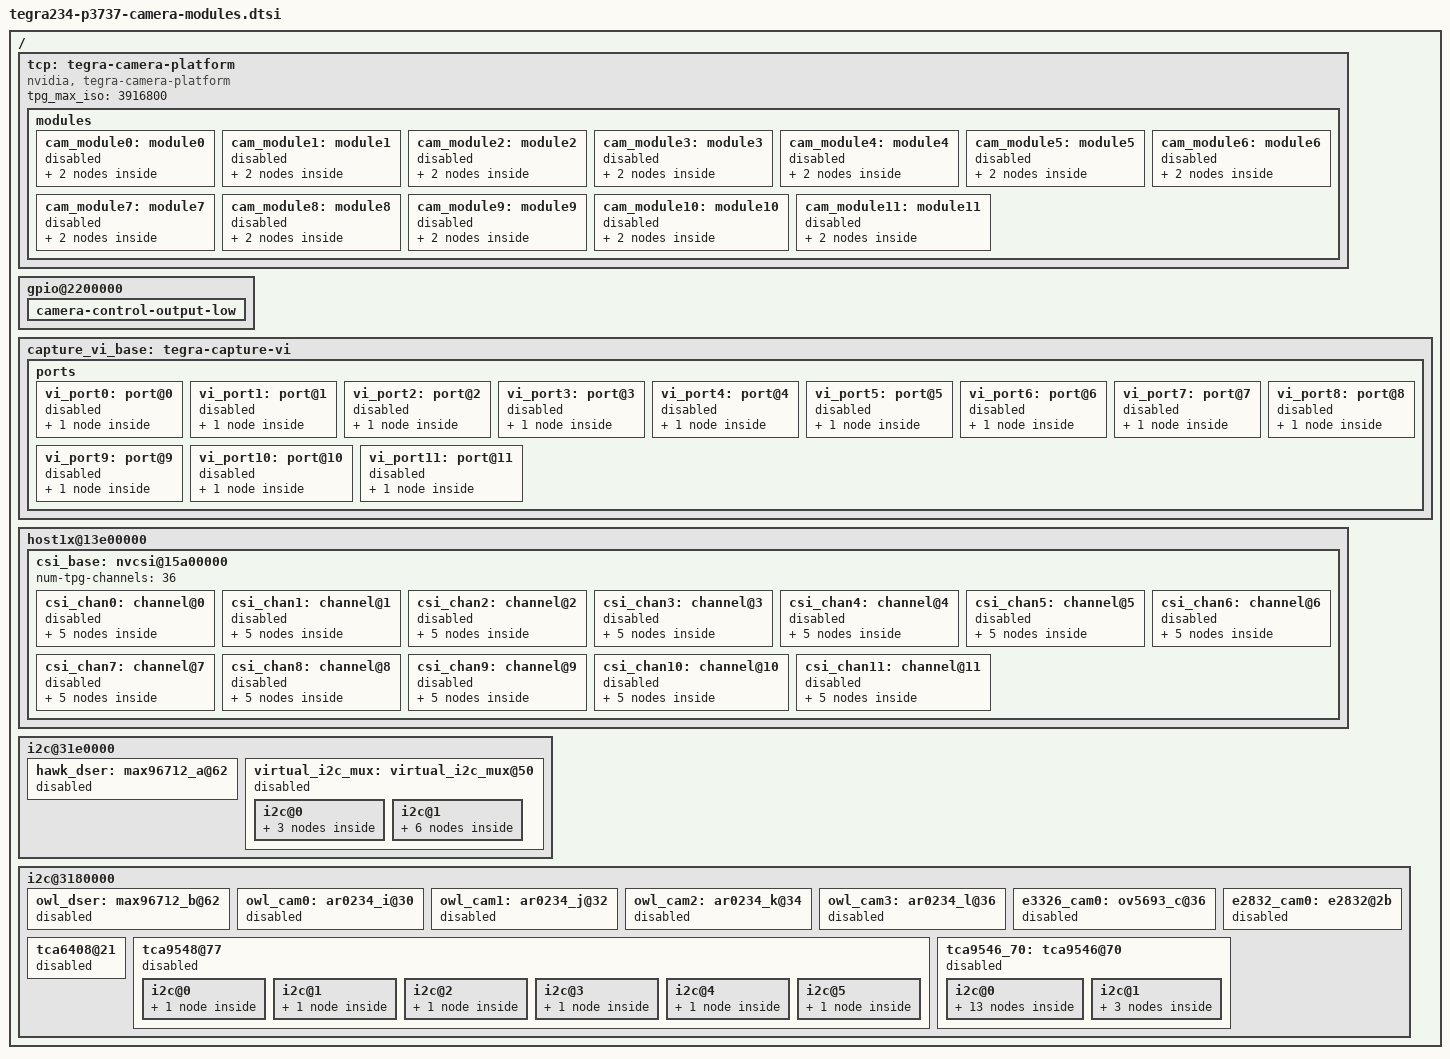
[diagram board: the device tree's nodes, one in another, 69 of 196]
/*
 * Copyright (c) 2023, NVIDIA CORPORATION.  All rights reserved.
 *
 * This program is free software; you can redistribute it and/or modify it
 * under the terms and conditions of the GNU General Public License,
 * version 2, as published by the Free Software Foundation.
 *
 * This program is distributed in the hope it will be useful, but WITHOUT
 * ANY WARRANTY; without even the implied warranty of MERCHANTABILITY or
 * FITNESS FOR A PARTICULAR PURPOSE.  See the GNU General Public License for
 * more details.
 *
 * You should have received a copy of the GNU General Public License
 * along with this program.  If not, see <http://www.gnu.org/licenses/>.
 */

/* These headers don't exist yet.
 * TODO: add below headers for corresponding sensor modules.
 * #include "tegra234-p3737-0000-camera-e3377-a00.dtsi"
 * #include "tegra234-p3737-0000-camera-e3326-a00.dtsi"
 * #include "tegra234-p3737-0000-camera-vivid.dtsi"
 * #include "tegra234-p3737-0000-camera-imx274-a00.dtsi"
 */

#include "tegra234-p3737-0000-camera-ar0234-a00.dtsi"
#include "tegra234-p3737-0000-camera-p3762-a00.dtsi"
#include "tegra234-p3737-0000-camera-e3331-a00.dtsi"
#include "tegra234-p3737-0000-camera-e3333-a00.dtsi"
#include "tegra234-p3737-0000-camera-imx185-a00.dtsi"
#include "tegra234-p3737-0000-camera-imx390-a00.dtsi"
#include "tegra234-p3737-0000-camera-imx274-dual.dtsi"


#define CAM0_RST_L	TEGRA234_MAIN_GPIO(H, 3)
#define CAM0_PWDN	TEGRA234_MAIN_GPIO(H, 6)
#define CAM1_RST_L	TEGRA234_MAIN_GPIO(AC, 1)
#define CAM1_PWDN	TEGRA234_MAIN_GPIO(AC, 0)

/ {
	tegra-camera-platform {
		/**
		* tpg_max_iso = <>;
		* Max iso bw for 6 streams of tpg
		* streams * nvcsi_freq * PG_bitrate / RG10 * BPP
		* 6 * 102Mhz * 32 bits/ 10 bits * 2 Bps
		* = 3916.8 MBps
		*/
		tpg_max_iso = <3916800>;
	};

	/* set camera gpio direction to output */
	gpio@2200000 {
		camera-control-output-low {
			gpio-hog;
			output-low;
			gpios = <CAM0_RST_L 0 CAM0_PWDN 0
				 CAM1_RST_L 0 CAM1_PWDN 0>;
			label = "cam0-rst", "cam0-pwdn",
				"cam1-rst", "cam1-pwdn";
		};
	};

	/* all cameras are disabled by default */
	capture_vi_base: tegra-capture-vi {
		ports {
			vi_port0: port@0 {
				status = "disabled";
				vi_in0: endpoint {
					vc-id = <0>;
					status = "disabled";
				};
			};
			vi_port1: port@1 {
				status = "disabled";
				vi_in1: endpoint {
					vc-id = <0>;
					status = "disabled";
				};
			};
			vi_port2: port@2 {
				status = "disabled";
				vi_in2: endpoint {
					vc-id = <0>;
					status = "disabled";
				};
			};
			vi_port3: port@3 {
				status = "disabled";
				vi_in3: endpoint {
					vc-id = <0>;
					status = "disabled";
				};
			};
			vi_port4: port@4 {
				status = "disabled";
				vi_in4: endpoint {
					vc-id = <0>;
					status = "disabled";
				};
			};
			vi_port5: port@5 {
				status = "disabled";
				vi_in5: endpoint {
					vc-id = <0>;
					status = "disabled";
				};
			};
			vi_port6: port@6 {
				status = "disabled";
				vi_in6: endpoint {
					vc-id = <0>;
					status = "disabled";
				};
			};
			vi_port7: port@7 {
				status = "disabled";
				vi_in7: endpoint {
					vc-id = <0>;
					status = "disabled";
				};
			};
			vi_port8: port@8 {
				status = "disabled";
				vi_in8: endpoint {
					vc-id = <0>;
					status = "disabled";
				};
			};
			vi_port9: port@9 {
				status = "disabled";
				vi_in9: endpoint {
					vc-id = <0>;
					status = "disabled";
				};
			};
			vi_port10: port@10 {
				status = "disabled";
				vi_in10: endpoint {
					vc-id = <0>;
					status = "disabled";
				};
			};
			vi_port11: port@11 {
				status = "disabled";
				vi_in11: endpoint {
					vc-id = <0>;
					status = "disabled";
				};
			};
		};
	};

	host1x@13e00000 {
		csi_base: nvcsi@15a00000 {
			num-tpg-channels = <36>;
			csi_chan0: channel@0 {
				status = "disabled";
				ports {
					csi_chan0_port0: port@0 {
						status = "disabled";
						csi_in0: endpoint@0 {
							status = "disabled";
						};
					};
					csi_chan0_port1: port@1 {
						status = "disabled";
						csi_out0: endpoint@1 {
							status = "disabled";
						};
					};
				};
			};
			csi_chan1: channel@1 {
				status = "disabled";
				ports {
					csi_chan1_port0: port@0 {
						status = "disabled";
						csi_in1: endpoint@2 {
							status = "disabled";
						};
					};
					csi_chan1_port1: port@1 {
						status = "disabled";
						csi_out1: endpoint@3 {
							status = "disabled";
						};
					};
				};
			};
			csi_chan2: channel@2 {
				status = "disabled";
				ports {
					csi_chan2_port0: port@0 {
						status = "disabled";
						csi_in2: endpoint@4 {
							status = "disabled";
						};
					};
					csi_chan2_port1: port@1 {
						status = "disabled";
						csi_out2: endpoint@5 {
							status = "disabled";
						};
					};
				};
			};
			csi_chan3: channel@3 {
				status = "disabled";
				ports {
					csi_chan3_port0: port@0 {
						status = "disabled";
						csi_in3: endpoint@6 {
							status = "disabled";
						};
					};
					csi_chan3_port1: port@1 {
						status = "disabled";
						csi_out3: endpoint@7 {
							status = "disabled";
						};
					};
				};
			};
			csi_chan4: channel@4 {
				status = "disabled";
				ports {
					csi_chan4_port0: port@0 {
						status = "disabled";
						csi_in4: endpoint@8 {
							status = "disabled";
						};
					};
					csi_chan4_port1: port@1 {
						status = "disabled";
						csi_out4: endpoint@9 {
							status = "disabled";
						};
					};
				};
			};
			csi_chan5: channel@5 {
				status = "disabled";
				ports {
					csi_chan5_port0: port@0 {
						status = "disabled";
						csi_in5: endpoint@10 {
							status = "disabled";
						};
					};
					csi_chan5_port1: port@1 {
						status = "disabled";
						csi_out5: endpoint@11 {
							status = "disabled";
						};
					};
				};
			};
			csi_chan6: channel@6 {
				status = "disabled";
				ports {
					csi_chan6_port0: port@0 {
						status = "disabled";
						csi_in6: endpoint@12 {
							status = "disabled";
						};
					};
					csi_chan6_port1: port@1 {
						status = "disabled";
						csi_out6: endpoint@13 {
							status = "disabled";
						};
					};
				};
			};
			csi_chan7: channel@7 {
				status = "disabled";
				ports {
					csi_chan7_port0: port@0 {
						status = "disabled";
						csi_in7: endpoint@14 {
							status = "disabled";
						};
					};
					csi_chan7_port1: port@1 {
						status = "disabled";
						csi_out7: endpoint@15 {
							status = "disabled";
						};
					};
				};
			};
			csi_chan8: channel@8 {
				status = "disabled";
				ports {
					csi_chan8_port0: port@0 {
						status = "disabled";
						csi_in8: endpoint@16 {
							status = "disabled";
						};
					};
					csi_chan8_port1: port@1 {
						status = "disabled";
						csi_out8: endpoint@17 {
							status = "disabled";
						};
					};
				};
			};
			csi_chan9: channel@9 {
				status = "disabled";
				ports {
					csi_chan9_port0: port@0 {
						status = "disabled";
						csi_in9: endpoint@18 {
							status = "disabled";
						};
					};
					csi_chan9_port1: port@1 {
						status = "disabled";
						csi_out9: endpoint@19 {
							status = "disabled";
						};
					};
				};
			};
			csi_chan10: channel@10 {
				status = "disabled";
				ports {
					csi_chan10_port0: port@0 {
						status = "disabled";
						csi_in10: endpoint@20 {
							status = "disabled";
						};
					};
					csi_chan10_port1: port@1 {
						status = "disabled";
						csi_out10: endpoint@21 {
							status = "disabled";
						};
					};
				};
			};
			csi_chan11: channel@11 {
				status = "disabled";
				ports {
					csi_chan11_port0: port@0 {
						status = "disabled";
						csi_in11: endpoint@22 {
							status = "disabled";
						};
					};
					csi_chan11_port1: port@1 {
						status = "disabled";
						csi_out11: endpoint@23 {
							status = "disabled";
						};
					};
				};
			};
		};
	};

	i2c@31e0000 {
		hawk_dser: max96712_a@62 {
			status = "disabled";
		};
		virtual_i2c_mux: virtual_i2c_mux@50 {
			status = "disabled";
			i2c@0 {
				hawk_bmi: bmi088_a@69 {
					status = "disabled";
				};
				hawk_cam0: ar0234_a@30 {
					status = "disabled";
				};
				hawk_cam1: ar0234_b@31 {
					status = "disabled";
				};
			};
			i2c@1 {
				hawk_cam2: ar0234_c@32 {
					status = "disabled";
				};
				hawk_cam3: ar0234_d@33 {
					status = "disabled";
				};
				hawk_cam4: ar0234_e@34 {
					status = "disabled";
				};
				hawk_cam5: ar0234_f@35 {
					status = "disabled";
				};
				hawk_cam6: ar0234_g@36 {
					status = "disabled";
				};
				hawk_cam7: ar0234_h@37 {
					status = "disabled";
				};
			};
		};
	};
	i2c@3180000 {
		owl_dser: max96712_b@62 {
			status = "disabled";
		};
		owl_cam0: ar0234_i@30 {
			status = "disabled";
		};
		owl_cam1: ar0234_j@32 {
			status = "disabled";
		};
		owl_cam2: ar0234_k@34 {
			status = "disabled";
		};
		owl_cam3: ar0234_l@36 {
			status = "disabled";
		};
		e3326_cam0: ov5693_c@36 {
			status = "disabled";
		};
		e2832_cam0: e2832@2b {
			status = "disabled";
		};
		tca6408@21 {
			status = "disabled";
		};
		tca9548@77 {
			status = "disabled";
			i2c@0 {
				e3333_cam0: ov5693_a@36 {
					status = "disabled";
				};
			};
			i2c@1 {
				e3333_cam1: ov5693_b@36 {
					status = "disabled";
				};
			};
			i2c@2 {
				e3333_cam2: ov5693_c@36 {
					status = "disabled";
				};
			};
			i2c@3 {
				e3333_cam3: ov5693_d@36 {
					status = "disabled";
				};
			};
			i2c@4 {
				e3333_cam4: ov5693_e@36 {
					status = "disabled";
				};
			};
			i2c@5 {
				e3333_cam5: ov5693_g@36 {
					status = "disabled";
				};
			};
		};
		tca9546_70: tca9546@70 {
			status = "disabled";
			i2c@0 {
				dual_hawk0:dual_hawk_a@18 {
					status = "disabled";
				};
				dual_hawk1:dual_hawk_b@10 {
					status = "disabled";
				};
				pca9570_a_24: pca9570_a@24 {
					status = "disabled";
				};
				imx274_cam0: imx274_a@1a {
					status = "disabled";
				};
				imx185_cam0: imx185_a@1a {
					status = "disabled";
				};
				e3331_cam0: imx318_a@10 {
					status = "disable";
				};
				max96712_dser: single_max96712_a@62 {
					status = "disabled";
				};
				max9296_dser: max9296@48 {
					status = "disabled";
				};
				max9295_prim: max9295_prim@62 {
					status = "disabled";
				};
				max9295_ser0: max9295_a@40 {
					status = "disabled";
				};
				max9295_ser1: max9295_b@60 {
					status = "disabled";
				};
				imx390_cam0: imx390_a@1b {
					status = "disabled";
				};
				imx390_cam1: imx390_b@1c {
					status = "disabled";
				};
			};
			i2c@1 {
				dual_hawk2:dual_hawk_c@18 {
					status = "disabled";
				};
				dual_hawk3:dual_hawk_d@10 {
					status = "disabled";
				};
				imx274_cam1: imx274_c@1a {
					status = "disabled";
				};
			};
		};
	};

	tcp: tegra-camera-platform {
		compatible = "nvidia, tegra-camera-platform";
		modules {
			cam_module0: module0 {
				status = "disabled";
				cam_module0_drivernode0: drivernode0 {
					status = "disabled";
				};
				cam_module0_drivernode1: drivernode1 {
					status = "disabled";
					pcl_id = "v4l2_lens";
				};
			};
			cam_module1: module1 {
				status = "disabled";
				cam_module1_drivernode0: drivernode0 {
					status = "disabled";
				};
				cam_module1_drivernode1: drivernode1 {
					status = "disabled";
					pcl_id = "v4l2_lens";
				};
			};
			cam_module2: module2 {
				status = "disabled";
				cam_module2_drivernode0: drivernode0 {
					status = "disabled";
				};
				cam_module2_drivernode1: drivernode1 {
					status = "disabled";
					pcl_id = "v4l2_lens";
				};
			};
			cam_module3: module3 {
				status = "disabled";
				cam_module3_drivernode0: drivernode0 {
					status = "disabled";
				};
				cam_module3_drivernode1: drivernode1 {
					status = "disabled";
					pcl_id = "v4l2_lens";
				};
			};
			cam_module4: module4 {
				status = "disabled";
				cam_module4_drivernode0: drivernode0 {
					status = "disabled";
				};
				cam_module4_drivernode1: drivernode1 {
					status = "disabled";
					pcl_id = "v4l2_lens";
				};
			};
			cam_module5: module5 {
				status = "disabled";
				cam_module5_drivernode0: drivernode0 {
					status = "disabled";
				};
				cam_module5_drivernode1: drivernode1 {
					status = "disabled";
					pcl_id = "v4l2_lens";
				};
			};
			cam_module6: module6 {
				status = "disabled";
				cam_module6_drivernode0: drivernode0 {
					status = "disabled";
				};
				cam_module6_drivernode1: drivernode1 {
					status = "disabled";
					pcl_id = "v4l2_lens";
				};
			};
			cam_module7: module7 {
				status = "disabled";
				cam_module7_drivernode0: drivernode0 {
					status = "disabled";
				};
				cam_module7_drivernode1: drivernode1 {
					status = "disabled";
					pcl_id = "v4l2_lens";
				};
			};
			cam_module8: module8 {
				status = "disabled";
				cam_module8_drivernode0: drivernode0 {
					status = "disabled";
				};
				cam_module8_drivernode1: drivernode1 {
					status = "disabled";
					pcl_id = "v4l2_lens";
				};
			};
			cam_module9: module9 {
				status = "disabled";
				cam_module9_drivernode0: drivernode0 {
					status = "disabled";
				};
				cam_module9_drivernode1: drivernode1 {
					status = "disabled";
					pcl_id = "v4l2_lens";
				};
			};
			cam_module10: module10 {
				status = "disabled";
				cam_module10_drivernode0: drivernode0 {
					status = "disabled";
				};
				cam_module10_drivernode1: drivernode1 {
					status = "disabled";
					pcl_id = "v4l2_lens";
				};
			};
			cam_module11: module11 {
				status = "disabled";
				cam_module11_drivernode0: drivernode0 {
					status = "disabled";
				};
				cam_module11_drivernode1: drivernode1 {
					status = "disabled";
					pcl_id = "v4l2_lens";
				};
			};
		};
	};
};
